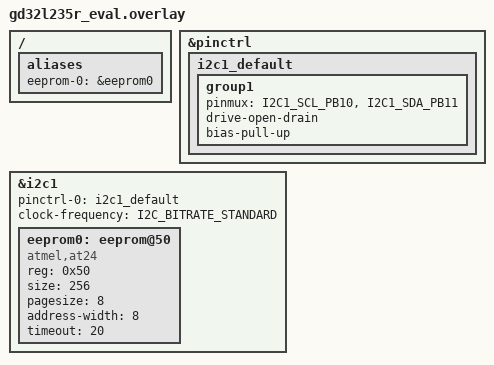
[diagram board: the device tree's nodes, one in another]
/*
 * Copyright (c) 2026 GigaDevice Semiconductor Inc.
 * SPDX-License-Identifier: Apache-2.0
 */

#include <zephyr/dt-bindings/i2c/i2c.h>

/ {
	aliases {
		eeprom-0 = &eeprom0;
	};
};

&pinctrl {
	i2c1_default: i2c1_default {
		group1 {
			pinmux = <I2C1_SCL_PB10>, <I2C1_SDA_PB11>;
			drive-open-drain;
			bias-pull-up;
		};
	};
};

&i2c1 {
	status = "okay";
	pinctrl-0 = <&i2c1_default>;
	pinctrl-names = "default";
	clock-frequency = <I2C_BITRATE_STANDARD>;

	eeprom0: eeprom@50 {
		compatible = "atmel,at24";
		reg = <0x50>;
		size = <256>;
		pagesize = <8>;
		address-width = <8>;
		timeout = <20>;
		status = "okay";
	};
};
